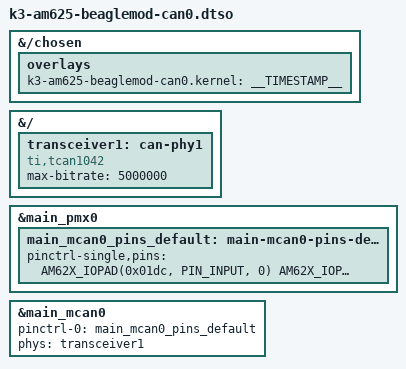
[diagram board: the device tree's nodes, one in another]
// SPDX-License-Identifier: GPL-2.0
/*
 * Copyright (C) 2022 Texas Instruments Incorporated - https://www.ti.com/
 */

/dts-v1/;
/plugin/;

#include "k3-pinctrl.h"

/*
 * Helper to show loaded overlays under: /proc/device-tree/chosen/overlays/
 */
&{/chosen} {
	overlays {
		k3-am625-beaglemod-can0.kernel = __TIMESTAMP__;
	};
};

&{/} {
	transceiver1: can-phy1 {
		compatible = "ti,tcan1042";
		#phy-cells = <0>;
		max-bitrate = <5000000>;
	};
};

&main_pmx0 {
	main_mcan0_pins_default: main-mcan0-pins-default {
		pinctrl-single,pins = <
			AM62X_IOPAD(0x01dc, PIN_INPUT, 0) /* (E15) MCAN0_RX */
			AM62X_IOPAD(0x01d8, PIN_OUTPUT, 0) /* (C15) MCAN0_TX */
		>;
	};
};

&main_mcan0 {
	pinctrl-names = "default";
	pinctrl-0 = <&main_mcan0_pins_default>;
	phys = <&transceiver1>;
	status = "okay";
};
